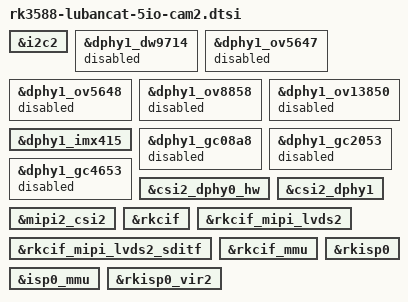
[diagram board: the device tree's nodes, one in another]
&i2c2 {
	status = "okay";
};

&dphy1_dw9714 {
	status = "disabled";
};

&dphy1_ov5647 {
	status = "disabled";
};

&dphy1_ov5648 {
	status = "disabled";
};

&dphy1_ov8858 {
	status = "disabled";
};

&dphy1_ov13850 {
	status = "disabled";
};

&dphy1_imx415 {
	status = "okay";
};

&dphy1_gc08a8 {
	status = "disabled";
};

&dphy1_gc2053 {
	status = "disabled";
};

&dphy1_gc4653 {
	status = "disabled";
};

&csi2_dphy0_hw {
	status = "okay";
};

&csi2_dphy1 {
	status = "okay";
};

&mipi2_csi2 {
	status = "okay";
};

&rkcif {
	status = "okay";
};

&rkcif_mipi_lvds2 {
	status = "okay";
};

&rkcif_mipi_lvds2_sditf {
	status = "okay";
};

&rkcif_mmu {
	status = "okay";
};

&rkisp0 {
	status = "okay";
};

&isp0_mmu {
	status = "okay";
};

&rkisp0_vir2 {
	status = "okay";
};
